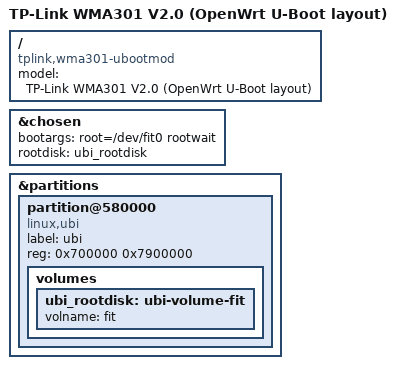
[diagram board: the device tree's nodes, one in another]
// SPDX-License-Identifier: GPL-2.0-or-later OR MIT

/dts-v1/;
#include "mt7981b-tplink-wma301-common.dtsi"

/ {
	model = "TP-Link WMA301 V2.0 (OpenWrt U-Boot layout)";
	compatible = "tplink,wma301-ubootmod", "mediatek,mt7981";
};

&chosen {
	bootargs = "root=/dev/fit0 rootwait";
	rootdisk = <&ubi_rootdisk>;
};

&partitions {
	partition@580000 {
		compatible = "linux,ubi";
		label = "ubi";
		reg = <0x700000 0x7900000>;

		volumes {
			ubi_rootdisk: ubi-volume-fit {
				volname = "fit";
			};
		};
	};
};
